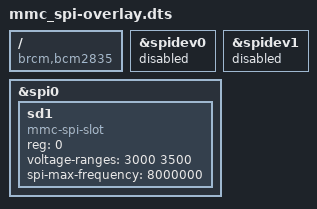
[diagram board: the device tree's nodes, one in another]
/dts-v1/;
/plugin/;

/ {
   compatible = "brcm,bcm2835", "brcm,bcm2836", "brcm,bcm2708", "brcm,bcm2709", "brcm,bcm2710";

   fragment@0 {
        target = <&spidev0>;
        __overlay__ {
            status = "disabled";
        };
   };
   fragment@1 {
        target = <&spidev1>;
        __overlay__ {
            status = "disabled";
        };
   };
   fragment@2 {
      target = <&spi0>;
      __overlay__ {
         status = "okay";
         sd1 {
                reg = <0>;
                status = "okay";
                compatible = "mmc-spi-slot";
                voltage-ranges = <3000 3500>;
                spi-max-frequency = <8000000>;
         };
      };
   };
};


